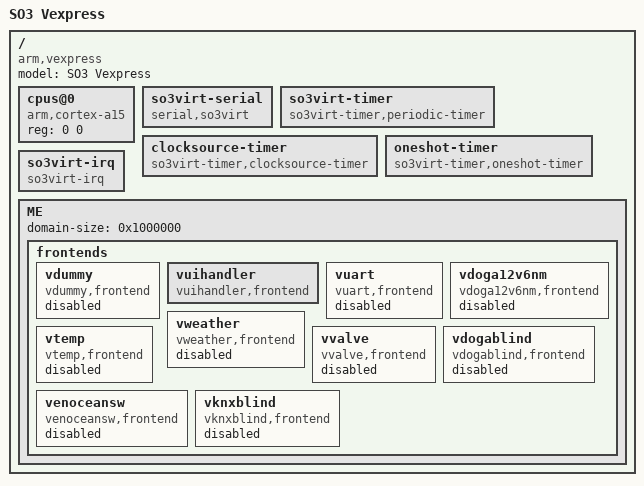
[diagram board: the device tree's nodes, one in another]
/*
 * Copyright (C) 2016-2018 Daniel Rossier <daniel.rossier@soo.tech>
 *
 * This program is free software; you can redistribute it and/or modify
 * it under the terms of the GNU General Public License version 2 as
 * published by the Free Software Foundation.
 *
 * This program is distributed in the hope that it will be useful,
 * but WITHOUT ANY WARRANTY; without even the implied warranty of
 * MERCHANTABILITY or FITNESS FOR A PARTICULAR PURPOSE.  See the
 * GNU General Public License for more details.
 *
 * You should have received a copy of the GNU General Public License
 * along with this program; if not, write to the Free Software
 * Foundation, Inc., 51 Franklin St, Fifth Floor, Boston, MA  02110-1301  USA
 *
 */

/dts-v1/;

#include "skeleton.dtsi"

/ {
	model = "SO3 Vexpress";
	compatible = "arm,vexpress";

	cpus@0 {
		device_type = "cpu";
		compatible = "arm,cortex-a15";
		reg = <0 0>;
	};
	
	so3virt-serial {
		compatible = "serial,so3virt";
		status = "ok";
	};
		
	/* SO3 virtual timer managed by AVZ */
 
	so3virt-timer {
		compatible = "so3virt-timer,periodic-timer";
		status = "ok";
	};
 
	/* Free-running clocksource */
	clocksource-timer {
		compatible = "so3virt-timer,clocksource-timer";
		status = "ok";
	};
		
	oneshot-timer {
		compatible ="so3virt-timer,oneshot-timer";
		status = "ok";
	};
	
	so3virt-irq {
		compatible = "so3virt-irq";
		status = "ok";
	};
	
	
	ME: ME {
#if 0 /* If used without ramfs */
		domain-size = <0x400000>; /* 4 MB */
#endif			
		domain-size = <0x1000000>; /* 16 MB */
		
		frontends {
		
			vdummy {
				compatible = "vdummy,frontend";
				status = "disabled";
			};
	
			vuihandler {
				compatible = "vuihandler,frontend";
				status = "ok";
			};
    
			vuart {
				compatible = "vuart,frontend";
				status = "disabled";
			};
			
			vdoga12v6nm {
            	compatible = "vdoga12v6nm,frontend";
            	status = "disabled";
            };
            
            vweather {
            	compatible = "vweather,frontend";
            	status = "disabled";
        	};
            
            vtemp {
            	compatible = "vtemp,frontend";
            	status = "disabled";
        	};
            
            vvalve {
            	compatible = "vvalve,frontend";
            	status = "disabled";
        	};
            
            vdogablind {
            	compatible = "vdogablind,frontend";
            	status = "disabled";
        	};
            
            venoceansw {
            	compatible = "venoceansw,frontend";
            	status = "disabled";
        	};
            
            vknxblind {
            	compatible = "vknxblind,frontend";
            	status = "disabled";
        	};
			
		};
	
	};
};
